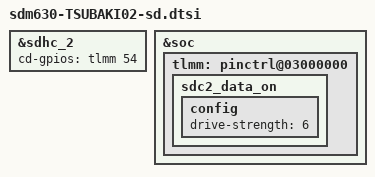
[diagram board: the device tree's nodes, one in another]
/* This software is contributed or developed by KYOCERA Corporation.
 * (C) 2018 KYOCERA Corporation
 *
 * This program is free software; you can redistribute it and/or modify
 * it under the terms of the GNU General Public License version 2 and
 * only version 2 as published by the Free Software Foundation.
 *
 * This program is distributed in the hope that it will be useful,
 * but WITHOUT ANY WARRANTY; without even the implied warranty of
 * MERCHANTABILITY or FITNESS FOR A PARTICULAR PURPOSE.  See the
 * GNU General Public License for more details.
 */

&sdhc_2 {
	/*modify the sd detected gpio status*/
	cd-gpios = <&tlmm 54 0x0>;
};
&soc {
        tlmm: pinctrl@03000000 {
                sdc2_data_on: sdc2_data_on {
                        config {
                                drive-strength = <6>; /* 6 MA */
                        };
                };
        };
};
